# psoc4hvpaspm10 register map
Vendor: Infineon Technologies; Series: PSOC4HVPASPM10; File version: 1.0
CPU: CM0PLUS r0p1, little endian, MPU, no FPU, VTOR, 2 interrupt priority bits, 32 interrupts
Registers are 32-bit, read-write, reset 0x0 unless marked. A register's access mark holds for its fields unless they carry their own. Offsets are from the block's base; [hi:lo] are bit positions.

## SPCIF — Flash Control Interface
Base 0x40110000
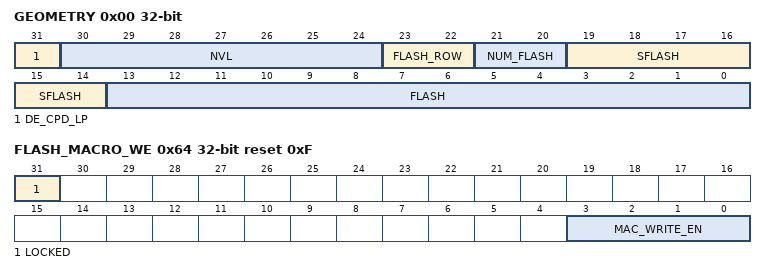
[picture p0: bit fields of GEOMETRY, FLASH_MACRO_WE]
0x00 GEOMETRY (reset mask 0x80000000) — Flash/NVL geometry information
  [31] DE_CPD_LP — 0': SRAM busy wait loop has not been copied. '1': Busy wait loop has been written into SRAM.
  [30:24] NVL ro — NVLatch size in Byte multiples (chip dependent): '0': 0 Bytes '1': 1 Byte ... '127': 127 Bytes
  [23:22] FLASH_ROW ro — Page size in 64 Byte multiples (chip dependent): '0': 64 byte '1': 128 byte '2': 192 byte '3': 256 byte The page size is used to determine the number of Bytes in a page for Flash page based operations (e.g. PGM_PAGE). Note: the field name FLASH_ROW is misleading, as this field specifies the number of Bytes in a page, rather than the number of Bytes in a row. In a single plane flash macro architecture, a page consists of a single row. However, in a multi plane flash macro architecture, a page consists of multiple rows from different planes.
  [21:20] NUM_FLASH ro — Number of flash macros (chip dependent): '0': 1 flash macro '1': 2 flash macros '2': 3 flash macros '3': 4 flash macros
  [19:14] SFLASH ro — Supervisory flash capacity in 256 Byte multiples (chip dependent). If multiple flash macros are present, this field provides the supervisory flash capacity of all flash macros together: '0': 256 Bytes. '1': 2*256 Bytes. ... '63': 64*256 Bytes.
  [13:0] FLASH ro — Regular flash capacity in 256 Byte multiples (chip dependent). If multiple flash macros are present, this field provides the flash capacity of all flash macros together: '0': 256 Bytes. '1': 2*256 Bytes. ... '16383': 16384*256 Bytes.
0x1C NVL_WR_DATA — NVL write data register
  [7:0] DATA — Data to be written to NVLatch array
0x60 FLASH_LOCK wo
  [31:0] KEY — Write Only register that locks/unlocks access to the FLASH MACRO_WE register by writing a key value to the register. The Key is the 32 bit value '0xF56B3A81'. When this specific bit pattern is written to the register, write access to FLASH_MACRO_WE is toggled between locked and unlocked. The bit FLASH_MACRO_WE.LOCKED toggles upon receipt of the required key value.
0x64 FLASH_MACRO_WE reset 0xF — Flash Macro Write Enable
  [31] LOCKED ro — When set indicates that write access to FLASH_MACRO_WE.MAC_WRITE_EN is blocked. The value of this bit toggles when the key value is written into FLASH_LOCK.KEY.
  [3:0] MAC_WRITE_EN — Access control to Flash Macros Write Access. This is a bit mask where each bit controls Program/Erase Access to the corresponding Macro. When the bit is set to '1' then the Macro may be programmed/erased, when the bit is set to '0', the Macro content is locked. The content of this register may only be changed when FLASH_MACRO_WE.LOCKED is '0'.
0x7F0 INTR — SPCIF interrupt request register
  [0] TIMER write-1-clears — Timer counter value reaches '0'. Set to '1', when event is detected. Write INTR field with '1', to clear bit. Write INTR_SET field with '1', to set bit.
0x7F4 INTR_SET — SPCIF interrupt set request register
  [0] TIMER write-1-sets — Write INTR_SET field with '1' to set corresponding INTR field.
0x7F8 INTR_MASK — SPCIF interrupt mask register
  [0] TIMER — Mask for corresponding field in INTR register.
0x7FC INTR_MASKED ro — SPCIF interrupt masked request register
  [0] TIMER — Logical and of corresponding request and mask fields.

## SPCIF1 — Flash Control Interface
Base 0x40120000
Registers as SPCIF; these are added or differ:
0x7F0 INTR — SPCIF interrupt request register
  [0] TIMER write-1-clears — Timer counter value reaches '0'. Set to '1', when event is detected. Write INTR field with '1', to clear bit. Write INTR_SET field with '1', to set bit.
0x7F4 INTR_SET — SPCIF interrupt set request register
  [0] TIMER write-1-sets — Write INTR_SET field with '1' to set corresponding INTR field.
0x7F8 INTR_MASK — SPCIF interrupt mask register
  [0] TIMER — Mask for corresponding field in INTR register.
0x7FC INTR_MASKED ro — SPCIF interrupt masked request register
  [0] TIMER — Logical and of corresponding request and mask fields.

## CANFD0 (part 1 of 3) — CAN Controller
Base 0x40220000
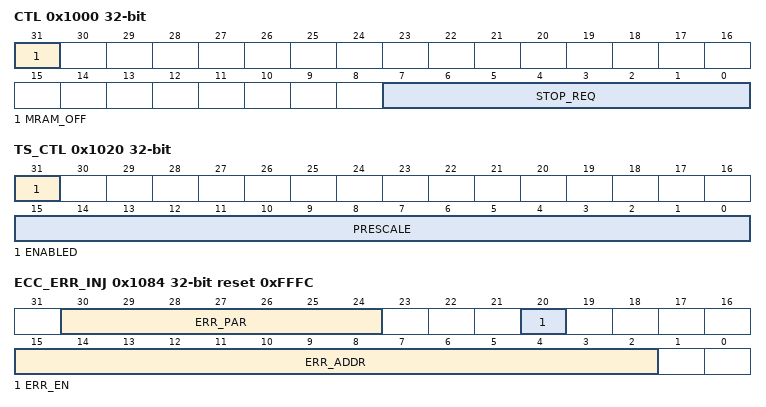
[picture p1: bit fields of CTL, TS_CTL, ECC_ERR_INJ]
0x1000 CTL — Global CAN control register
  [31] MRAM_OFF — MRAM off 0= Default MRAM on (with MRAM retained in DeepSleep). 1= Switch MRAM off (not retained) to save power. Before setting this bit all the CAN channels have to be powered down using the STOP_REQ/ACK bits. When the MRAM is off any access attempt to it is considered an address error (as if MRAM_SIZE=0). After switching the MRAM on again software needs to allow for a certain power up time before MRAM can be used, i.e. before STOP_REQ can be de-asserted. The power up time is equivalent to the system SRAM power up time specified in the CPUSS.RAM_PWR_DELAY_CTL register.
  [7:0] STOP_REQ
0x1004 STATUS ro — Global CAN status register
  [7:0] STOP_ACK — Clock Stop Acknowledge for each TTCAN IP. These bits are directly driven by m_ttcan_clkstop_ack of each TTCAN IP. When this bit is set the corresponding TTCAN IP clocks will be gated off, except HCLK will enabled for each AHB write
0x1010 INTR0_CAUSE ro — Consolidated interrupt0 cause register
  [7:0] INT0 — Show pending m_ttcan_int0 of each channel
0x1014 INTR1_CAUSE ro — Consolidated interrupt1 cause register
  [7:0] INT1 — Show pending m_ttcan_int1 of each channel
0x1020 TS_CTL — Time Stamp control register
  [31] ENABLED — Counter enable bit 0 = Count disabled. Stop counting up and keep the counter value 1 = Count enabled. Start counting up from the current value
  [15:0] PRESCALE — Time Stamp counter prescale value. When enabled divide the Host clock (HCLK) by PRESCALE+1 to create Time Stamp clock ticks.
0x1024 TS_CNT — Time Stamp counter value
  [15:0] VALUE — The counter value of the Time Stamp Counter. When enabled this counter will count Time Stamp clock ticks from the pre-scaler. When written this counter and the pre-scaler will reset to 0 (write data is ignored).
0x1080 ECC_CTL — ECC control
  [16] ECC_EN — Enable ECC for CANFD SRAM When disabled also all error injection functionality is disabled.
0x1084 ECC_ERR_INJ reset 0xFFFC — ECC error injection
  [30:24] ERR_PAR — ECC Parity bits to use for ECC error injection at address ERR_ADDR.
  [20] ERR_EN — Enable error injection (ECC_EN must be 1). When this bit is set the error parity (ERR_PAR) will be used when an AHB write is done to the ERR_ADDR address. When the error word is read a single or double error will be reported to the fault structure just like for a real ECC error (even if this bit is no longer set). When this bit is set (and ECC_EN=1) a non-correctable error (ECC or address error) for the ERR_ADDR will not be reported back to the CAN channel or AHB bus.
  [15:2] ERR_ADDR — Specifies the address of the word where an error will be injected on write or an non-correctable error will be suppressed. When the ERR_EN bit is set an error parity (ERR_PAR) is injected when any write, from bus or a CAN channel, is done to this address. When the ERR_EN bit is set and the access address matches ERR_ADDR then a non-correctable ECC error or an Address error will NOT result in a bus error or CAN channel shutdown. Note that error reporting to the fault structure cannot be suppressed.
